# R7FA6M1AD register map
Vendor: Renesas; Series: RA6; File version: 1.2
CPU: CM4 r0p1, little endian, MPU, FPU, VTOR, 4 interrupt priority bits
Registers are 8-bit, read-write, reset 0x0 unless marked. A register's access mark holds for its fields unless they carry their own. Offsets are from the block's base; [hi:lo] are bit positions; {n}, {i} and the like mark numbered series.

## CAC — Clock Frequency Accuracy Measurement Circuit
Base 0x40044600
0x00 CACR0 — CAC Control Register 0
  [0] CFME — Clock Frequency Measurement Enable.
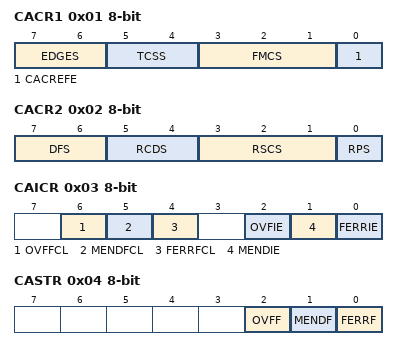
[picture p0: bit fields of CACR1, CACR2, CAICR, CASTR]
0x01 CACR1 — CAC Control Register 1
  [7:6] EDGES — Valid Edge Select
  [5:4] TCSS — Measurement Target Clock Frequency Division Ratio Select
  [3:1] FMCS — Measurement Target Clock Select
  [0] CACREFE — CACREF Pin Input Enable
0x02 CACR2 — CAC Control Register 2
  [7:6] DFS — Digital Filter Selection
  [5:4] RCDS — Measurement Reference Clock Frequency Division Ratio Select
  [3:1] RSCS — Measurement Reference Clock Select
  [0] RPS — Reference Signal Select
0x03 CAICR — CAC Interrupt Control Register
  [6] OVFFCL wo — OVFF Clear
  [5] MENDFCL wo — MENDF Clear
  [4] FERRFCL wo — FERRF Clear
  [2] OVFIE — Overflow Interrupt Request Enable
  [1] MENDIE — Measurement End Interrupt Request Enable
  [0] FERRIE — Frequency Error Interrupt Request Enable
0x04 CASTR ro — CAC Status Register
  [2] OVFF — Counter Overflow Flag
  [1] MENDF — Measurement End Flag
  [0] FERRF — Frequency Error Flag
0x06 CAULVR 16-bit — CAC Upper,Limit Value Setting Register
  [15:0] CAULVR — CAULVR is a 16-bit readable/writable register that stores the upper,limit value of the frequency.
0x08 CALLVR 16-bit — CAC Lower,Limit Value Setting Register
  [15:0] CALLVR — CALLVR is a 16-bit readable/writable register that stores the lower,limit value of the frequency.
0x0A CACNTBR 16-bit ro — CAC Counter Buffer Register
  [15:0] CACNTBR — CACNTBR is a 16-bit read,only register that retains the counter value at the time a valid reference signal edge is input

## DOC — Data Operation Circuit
Base 0x40054100
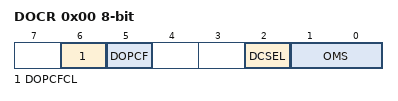
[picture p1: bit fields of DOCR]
0x00 DOCR — DOC Control Register
  [6] DOPCFCL — DOPCF Clear
  [5] DOPCF ro — Data Operation Circuit FlagIndicates the result of an operation.
  [2] DCSEL — Detection Condition Select
  [1:0] OMS — Operating Mode Select
0x02 DODIR 16-bit — DOC Data Input Register
  [15:0] DODIR — 16-bit read,write register in which 16-bit data for use in the operations are stored.
0x04 DODSR 16-bit — DOC Data Setting Register
  [15:0] DODSR — This register stores 16-bit data for use as a reference in data comparison mode. This register also stores the results of operations in data addition and data subtraction modes.

## IWDT — Independent Watchdog Timer
Base 0x40044400
0x00 IWDTRR reset 0xFF — IWDT Refresh Register
  [7:0] IWDTRR — The counter is refreshed by writing 0x00 and then writing 0xFF to this register.
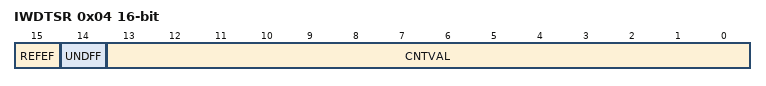
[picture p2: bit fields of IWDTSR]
0x04 IWDTSR 16-bit — IWDT Status Register
  [15] REFEF write-0-clears read-modifies — Refresh Error Flag
  [14] UNDFF write-0-clears read-modifies — Underflow Flag
  [13:0] CNTVAL ro — Counter ValueValue counted by the counter

## KINT — Key Interrupt Function
Base 0x40080000
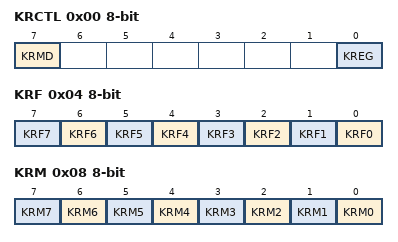
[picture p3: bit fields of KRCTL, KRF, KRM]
0x00 KRCTL — KEY Return Control Register
  [7] KRMD — Usage of Key Interrupt Flags(KR0 to KR7)
  [0] KREG — Detection Edge Selection (KRF0 to KRF7)
0x04 KRF write-0-clears read-modifies — KEY Return Flag Register
  [n] KRF{n} write-0-clears read-modifies (n=0..7) — Key interrupt flag {n}
0x08 KRM — KEY Return Mode Register
  [n] KRM{n} (n=0..7) — Key interrupt mode control {n}

## WDT — Watchdog Timer
Base 0x40044200
0x00 WDTRR reset 0xFF — WDT Refresh Register
  [7:0] WDTRR — WDTRR is an 8-bit register that refreshes the down,counter of the WDT.
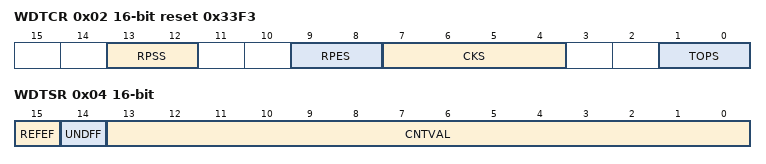
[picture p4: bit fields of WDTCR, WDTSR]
0x02 WDTCR 16-bit reset 0x33F3 — WDT Control Register
  [13:12] RPSS — Window Start Position Selection
  [9:8] RPES — Window End Position Selection
  [7:4] CKS — Clock Division Ratio Selection
  [1:0] TOPS — Timeout Period Selection
0x04 WDTSR 16-bit — WDT Status Register
  [15] REFEF write-0-clears read-modifies — Refresh Error Flag
  [14] UNDFF write-0-clears read-modifies — Underflow Flag
  [13:0] CNTVAL ro — Down,Counter ValueValue counted by the down,counter
0x06 WDTRCR reset 0x80 — WDT Reset Control Register
  [7] RSTIRQS — Reset Interrupt Request Selection
0x08 WDTCSTPR reset 0x80 — WDT Count Stop Control Register
  [7] SLCSTP — Sleep,Mode Count Stop Control
